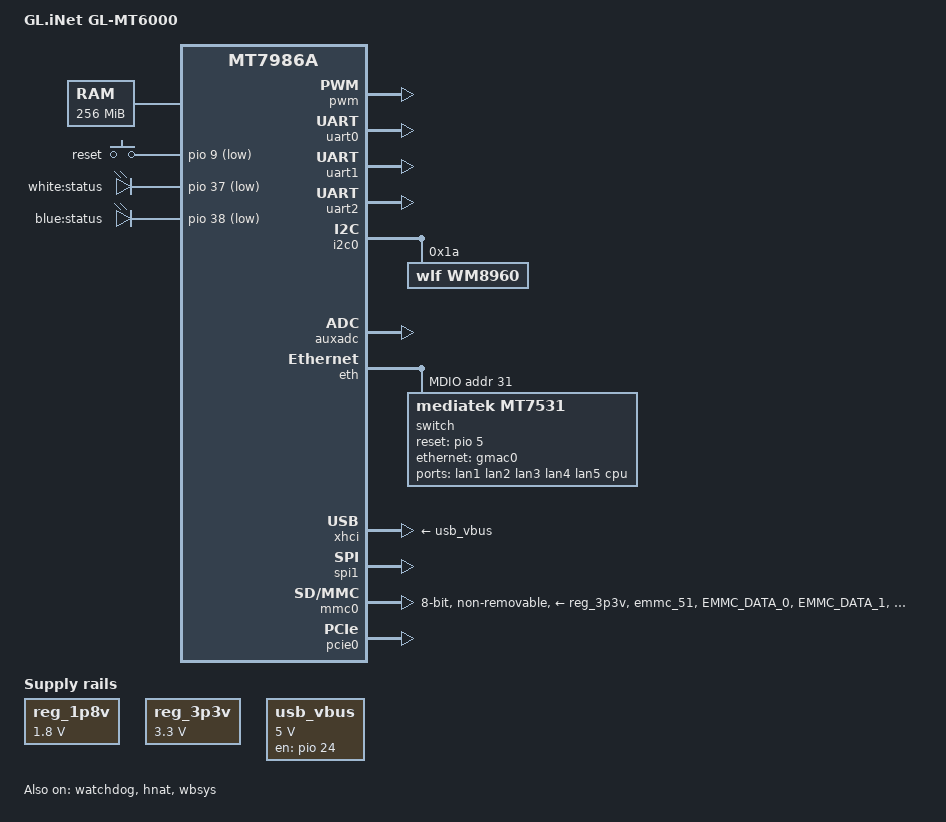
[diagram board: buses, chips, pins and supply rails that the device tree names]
/dts-v1/;
#include "mt7986a.dtsi"
#include "mt7986a-pinctrl.dtsi"
#include <dt-bindings/input/input.h>
#include <dt-bindings/gpio/gpio.h>
#include <dt-bindings/leds/common.h>
/ {
	model = "GL.iNet GL-MT6000";
 	compatible = "glinet,gl-mt6000","mediatek,mt7986a-emmc-rfb";
	chosen {
		bootargs = "console=ttyS0,115200n1 loglevel=8  \
				earlycon=uart8250,mmio32,0x11002000 \
				root=PARTLABEL=rootfs rootwait";
	};
	
	aliases {
		led-boot = &led_status_white;
 		led-failsafe = &led_status_white;
 		led-running = &led_status_blue;
 		led-upgrade = &led_status_blue;
	};

	memory {
		reg = <0 0x40000000 0 0x10000000>;
	};

	gpio-keys {
 		compatible = "gpio-keys";

 		button-reset {
 			label = "reset";
 			linux,code = <KEY_RESTART>;
 			gpios = <&pio 9 GPIO_ACTIVE_LOW>;
 		};

 	};
	
	leds {
		compatible = "gpio-leds";

		led_status_white: status_white {
 			label = "white:status";
 			gpios = <&pio 37 GPIO_ACTIVE_LOW>;
 		};

 		led_status_blue: status_blue {
 			label = "blue:status";
 			gpios = <&pio 38 GPIO_ACTIVE_LOW>;
 		};
	};

	reg_1p8v: regulator-1p8v {
		compatible = "regulator-fixed";
		regulator-name = "fixed-1.8V";
		regulator-min-microvolt = <1800000>;
		regulator-max-microvolt = <1800000>;
		regulator-boot-on;
		regulator-always-on;
	};

	reg_3p3v: regulator-3p3v {
		compatible = "regulator-fixed";
		regulator-name = "fixed-3.3V";
		regulator-min-microvolt = <3300000>;
		regulator-max-microvolt = <3300000>;
		regulator-boot-on;
		regulator-always-on;
	};


	usb_vbus: regulator-usb-vbus {
		compatible = "regulator-fixed";
		regulator-name = "usb_vbus";
		regulator-min-microvolt = <5000000>;
		regulator-max-microvolt = <5000000>;
		gpios = <&pio 24 GPIO_ACTIVE_HIGH>;
		enable-active-high;
		regulator-boot-on;
	};

	sound {
		compatible = "mediatek,mt7986-wm8960-machine";
		mediatek,platform = <&afe>;
		audio-routing = "Headphone", "HP_L",
				"Headphone", "HP_R",
				"LINPUT1", "AMIC",
				"RINPUT1", "AMIC";
		mediatek,audio-codec = <&wm8960>;
		status = "okay";
	};
};

&fan {
	pwms = <&pwm 1 50000 0>;
	status = "disabled";
};

&pwm {
	pinctrl-names = "default";
	pinctrl-0 = <&pwm0_pin &pwm1_pin_g1>;
	status = "okay";
};

&uart0 {
	status = "okay";
};

&uart1 {
	pinctrl-names = "default";
	pinctrl-0 = <&uart1_pins>;
	status = "okay";
};

&uart2 {
	pinctrl-names = "default";
	pinctrl-0 = <&uart2_pins>;
	status = "okay";
};

&i2c0 {
	pinctrl-names = "default";
	pinctrl-0 = <&i2c_pins>;
	status = "okay";

	wm8960: wm8960@1a {
		compatible = "wlf,wm8960";
		reg = <0x1a>;
	};
};

&auxadc {
	status = "okay";
};

&watchdog {
	status = "okay";
};

&eth {
	status = "okay";

	gmac0: mac@0 {
		compatible = "mediatek,eth-mac";
		reg = <0>;
		phy-mode = "2500base-x";
		ext-phy-reg = <1>;
		ext-phy-reset-gpios = <&pio 10 0>;
		fixed-link {
			speed = <2500>;
			full-duplex;
			pause;
		};	
	};

	gmac1: mac@1 {
		label = "wan";
		compatible = "mediatek,eth-mac";
		reg = <1>;
		phy-mode = "2500base-x";
		ext-phy-reg = <7>;
		ext-phy-reset-gpios = <&pio 19 0>;	
		fixed-link {
			speed = <2500>;
			full-duplex;
			pause;
		};
	};

	mdio: mdio-bus {
		#address-cells = <1>;
		#size-cells = <0>;
 		
		switch@0 {
			compatible = "mediatek,mt7531";
			reg = <31>;
			reset-gpios = <&pio 5 0>;

			ports {
				#address-cells = <1>;
				#size-cells = <0>;

				port@0 {
					reg = <0>;
					label = "lan1";
				};

				port@1 {
					reg = <1>;
					label = "lan2";
				};

				port@2 {
					reg = <2>;
					label = "lan3";
				};

				port@3 {
					reg = <3>;
					label = "lan4";
				};


				port@5 {
					reg = <5>;
					label = "lan5";
					phy-mode = "2500base-x";

					fixed-link {
						speed = <2500>;
						full-duplex;
						pause;
					};
				};

				port@6 {
					reg = <6>;
					label = "cpu";
					ethernet = <&gmac0>;
					phy-mode = "2500base-x";

					fixed-link {
						speed = <2500>;
						full-duplex;
						pause;
					};
				};
			};
		};
	};
};

&xhci {
 	vusb33-supply = <&reg_3p3v>;
 	vbus-supply = <&usb_vbus>;
 	status = "okay";
};

&hnat {
	mtketh-wan = "eth1";
	mtketh-lan = "lan";
	mtketh-max-gmac = <2>;
	status = "okay";
};

&spi1 {
	pinctrl-names = "default";
	pinctrl-0 = <&spic_pins_g2>;
	status = "okay";
};

&mmc0 {
	pinctrl-names = "default", "state_uhs";
	pinctrl-0 = <&mmc0_pins_default>;
	pinctrl-1 = <&mmc0_pins_uhs>;
	bus-width = <8>;
	max-frequency = <200000000>;
	cap-mmc-highspeed;
	mmc-hs200-1_8v;
	mmc-hs400-1_8v;
	hs400-ds-delay = <0x14014>;
	vmmc-supply = <&reg_3p3v>;
	vqmmc-supply = <&reg_1p8v>;
	non-removable;
	no-sd;
	no-sdio;
	status = "okay";
};

&pcie0 {
	pinctrl-names = "default";
	pinctrl-0 = <&pcie0_pins>;
	status = "okay";
};

&wbsys {
	status = "okay";
};

&pio {
	mmc0_pins_default: mmc0-pins-50-to-61-default {
		mux {
			function = "flash";
			groups = "emmc_51";
		};
		conf-cmd-dat {
			pins = "EMMC_DATA_0", "EMMC_DATA_1", "EMMC_DATA_2",
			       "EMMC_DATA_3", "EMMC_DATA_4", "EMMC_DATA_5",
			       "EMMC_DATA_6", "EMMC_DATA_7", "EMMC_CMD";
			input-enable;
			drive-strength = <MTK_DRIVE_4mA>;
			mediatek,pull-up-adv = <1>;	/* pull-up 10K */
		};
		conf-clk {
			pins = "EMMC_CK";
			drive-strength = <MTK_DRIVE_6mA>;
			mediatek,pull-down-adv = <2>;	/* pull-down 50K */
		};
		conf-ds {
			pins = "EMMC_DSL";
			mediatek,pull-down-adv = <2>;	/* pull-down 50K */
		};
		conf-rst {
			pins = "EMMC_RSTB";
			drive-strength = <MTK_DRIVE_4mA>;
			mediatek,pull-up-adv = <1>;	/* pull-up 10K */
		};
	};

	mmc0_pins_uhs: mmc0-pins-50-to-61-uhs {
		mux {
			function = "flash";
			groups = "emmc_51";
		};
		conf-cmd-dat {
			pins = "EMMC_DATA_0", "EMMC_DATA_1", "EMMC_DATA_2",
			       "EMMC_DATA_3", "EMMC_DATA_4", "EMMC_DATA_5",
			       "EMMC_DATA_6", "EMMC_DATA_7", "EMMC_CMD";
			input-enable;
			drive-strength = <MTK_DRIVE_4mA>;
			mediatek,pull-up-adv = <1>;	/* pull-up 10K */
		};
		conf-clk {
			pins = "EMMC_CK";
			drive-strength = <MTK_DRIVE_6mA>;
			mediatek,pull-down-adv = <2>;	/* pull-down 50K */
		};
		conf-ds {
			pins = "EMMC_DSL";
			mediatek,pull-down-adv = <2>;	/* pull-down 50K */
		};
		conf-rst {
			pins = "EMMC_RSTB";
			drive-strength = <MTK_DRIVE_4mA>;
			mediatek,pull-up-adv = <1>;	/* pull-up 10K */
		};
	};
};
